# RL6678_IP_SVD register map
Vendor: Realtek
Registers are 32-bit, read-write, reset 0x0 unless marked. A register's access mark holds for its fields unless they carry their own. Offsets are from the block's base; [hi:lo] are bit positions; <NAME> marks a mode.

## TRNG_REG
Base 0x41009000
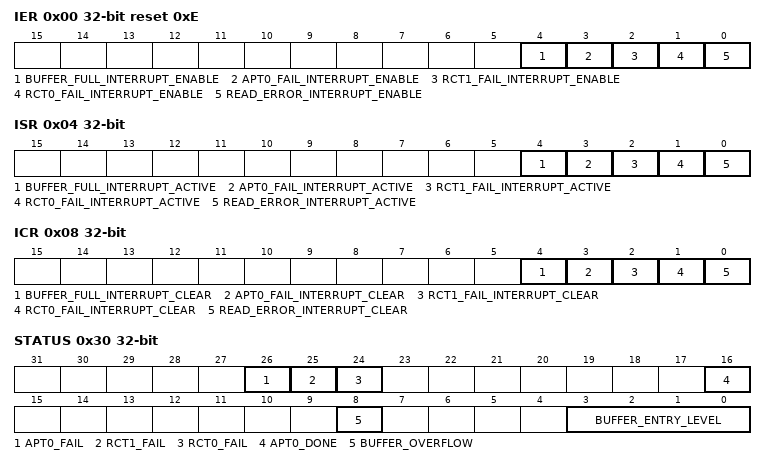
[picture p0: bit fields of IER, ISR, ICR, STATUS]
0x00 IER reset 0xE — Interrupt Enable Register
  [4] BUFFER_FULL_INTERRUPT_ENABLE — RNG buffer full interrupt enable
  [3] APT0_FAIL_INTERRUPT_ENABLE — Adaptive Proportion Test 0 fail interrupt enable
  [2] RCT1_FAIL_INTERRUPT_ENABLE — Repetition Count Test 1 fail interrupt enable
  [1] RCT0_FAIL_INTERRUPT_ENABLE — Repetition Count Test 0 fail interrupt enable
  [0] READ_ERROR_INTERRUPT_ENABLE — Read error interrupt enable. Trigger interrupt when reading RNG data register and RNG valid is not 0x1~0x8.
0x04 ISR ro — Interrupt Status Register
  [4] BUFFER_FULL_INTERRUPT_ACTIVE, [3] APT0_FAIL_INTERRUPT_ACTIVE, [2] RCT1_FAIL_INTERRUPT_ACTIVE, [1] RCT0_FAIL_INTERRUPT_ACTIVE, [0] READ_ERROR_INTERRUPT_ACTIVE
0x08 ICR wo — Interrupt Clear Register
  [4] BUFFER_FULL_INTERRUPT_CLEAR
  [3] APT0_FAIL_INTERRUPT_CLEAR — Clear the this interrupt also clear the error flags of APT0 health tests
  [2] RCT1_FAIL_INTERRUPT_CLEAR — Clear the this interrupt also clear the error flags of RCT1 health tests
  [1] RCT0_FAIL_INTERRUPT_CLEAR — Clear the this interrupt also clear the error flags of RCT0 health tests
  [0] READ_ERROR_INTERRUPT_CLEAR
0x0C FIFO_STATUS ro — Valid Register
  [3:0] RNG_VALID — Encoded status register. 0x0: buffer empty or APT is not done. 0x1~0x8: number of word are valid. 0xF: APT test fail
0x30 STATUS ro
  [26] APT0_FAIL — APT0 error detected
  [25] RCT1_FAIL — RCT1 error detected
  [24] RCT0_FAIL — RCT0 error detected
  [16] APT0_DONE — Adaptive Proportion Test done status. (APT test pass count >= APT done threshold setting)
  [8] BUFFER_OVERFLOW — Buffer overflow status. It is clear by RNG read out.
  [3:0] BUFFER_ENTRY_LEVEL — Number of 32-bit random number are valid. 0: empty 8: full
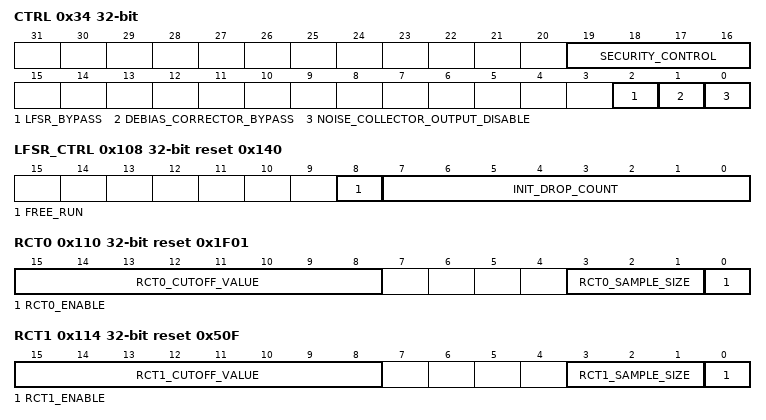
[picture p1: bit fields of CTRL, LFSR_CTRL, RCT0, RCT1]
0x34 CTRL — Control Register
  [19:16] SECURITY_CONTROL — If this field is equal to 0xA, the TRNG become a non-secure slave, and all the registers can be accessed by non-secure transaction. If this field is not equal to 0xA, the non-seucre transaction can only access address 0xC~0x30.
  [2] LFSR_BYPASS — LFSR bypass enable
  [1] DEBIAS_CORRECTOR_BYPASS — Debias corrector bypass enable
  [0] NOISE_COLLECTOR_OUTPUT_DISABLE
0x38 SW_RST wo — Software Reset Register
  [0] SW_RESET — Write 1 to trigger software reset.
0x108 LFSR_CTRL reset 0x140 — LFSR Control Register
  [8] FREE_RUN — 0x1: continuously run LFSR when no input data 0x0: only shift LFSR when input 1 bit data
  [7:0] INIT_DROP_COUNT — Discard number of bit after reset or re-init. Default shift out 64 bits in LFSR.
0x110 RCT0 reset 0x1F01 — Repetition Count Test 0 Control Register
  [15:8] RCT0_CUTOFF_VALUE — Cutoff value
  [3:1] RCT0_SAMPLE_SIZE — Number of bit per test sample. The sample size is the value add 1. 0: 1-bit 1: 2-bit ... 7: 8-bit
  [0] RCT0_ENABLE — Test enable
0x114 RCT1 reset 0x50F — Repetition Count Test 1 Control Register
  [15:8] RCT1_CUTOFF_VALUE — Cutoff value
  [3:1] RCT1_SAMPLE_SIZE — Number of bit per test sample. The sample size is the value add 1. 0: 1-bit 1: 2-bit ... 7: 8-bit
  [0] RCT1_ENABLE — Test enable
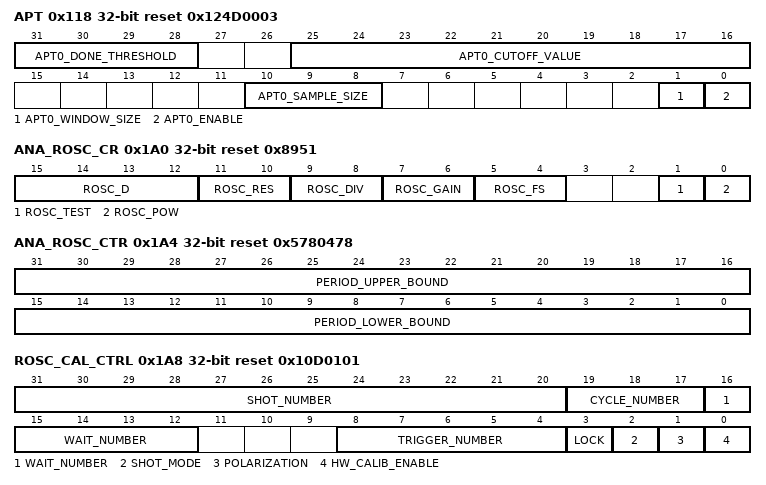
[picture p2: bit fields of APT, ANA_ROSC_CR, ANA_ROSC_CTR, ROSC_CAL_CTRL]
0x118 APT reset 0x124D0003 — Adaptive Proportion Test Control Register
  [31:28] APT0_DONE_THRESHOLD — Assert test done after how many test pass
  [25:16] APT0_CUTOFF_VALUE — Cutoff value
  [10:8] APT0_SAMPLE_SIZE — Number of bit per test sample. The sample size is the value add 1. 0: 1-bit 1: 2-bit ... 7: 8-bit
  [1] APT0_WINDOW_SIZE — 0: 512 bits 1: 1024 bits
  [0] APT0_ENABLE — Test enable
0x1A0 ANA_ROSC_CR reset 0x8951 — Analog ROSC Control Register
  [15:12] ROSC_D — (ROSC ISEL) ROSC calibration input data by F/W
  [11:10] ROSC_RES — ROSC noise resistor selection
  [9:8] ROSC_DIV — ROSC clock divider control register. 00: div1 01: div2 10: div3 11: div4
  [7:6] ROSC_GAIN — ROSC noise gain control
  [5:4] ROSC_FS — ROSC frequency range control register
  [1] ROSC_TEST — ROSC analog test signal enable
  [0] ROSC_POW — ROSC power-on control register
0x1A4 ANA_ROSC_CTR reset 0x5780478 — Analog ROSC Calibration Threshold Register
  [31:16] PERIOD_UPPER_BOUND — Calibration Period Upper Bound. The counter is clocked by bus clock to measure CLKOUT_ROSC period.
  [15:0] PERIOD_LOWER_BOUND — Calibration Period Lower Bound. If counter value < lower bound, the CLKOUT_ROSC frequency is too high.
0x1A8 ROSC_CAL_CTRL reset 0x10D0101 — ROSC Calibration Control Register
  [31:20] SHOT_NUMBER
  [19:17] CYCLE_NUMBER — 0x6 = 128 cycles. (this is an encode value). Number of ROSC clock cycle to trigger one calibration
  [16:12] WAIT_NUMBER — After ROSC_D change, the wait cycle number before next calibration procedure. It need to take about 1us to make the OSC stable.
  [8:4] TRIGGER_NUMBER — The value of ROSC_D will be adjusted if CKOUT_ROSC is too high/low more than trig_num times.
  [3] LOCK — Force rosc_lock to 1. The NS start to sample when rosc_lock is high. The lock indicate the OCS is stable measure by sensor.
  [2] SHOT_MODE
  [1] POLARIZATION — Polarization of ROSC_D in Calibration. 0: too low -> ROSC_D increases 1: too high -> ROSC_D decreases
  [0] HW_CALIB_ENABLE — 1: control ROSC_D by HW sensor logic. 0: control ROSC_D by SW.
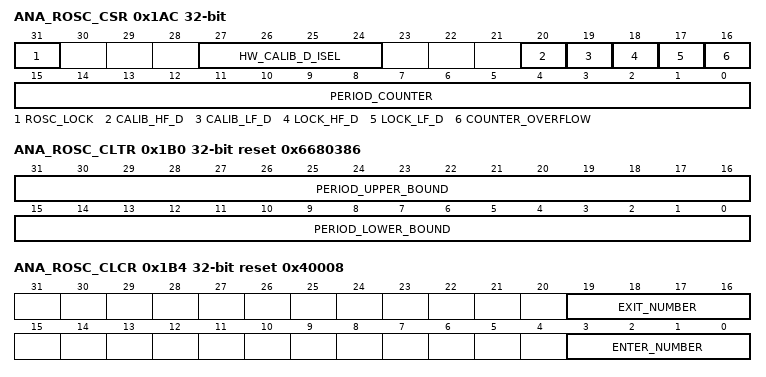
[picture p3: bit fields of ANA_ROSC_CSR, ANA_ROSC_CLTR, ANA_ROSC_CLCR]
0x1AC ANA_ROSC_CSR ro — Analog ROSC Calibration Status Register
  [31] ROSC_LOCK — ROSC is LOCK. It means CKOUT_ROSC is stable
  [27:24] HW_CALIB_D_ISEL — The value of ROSC_D generated by Speed Sensor hardware
  [20] CALIB_HF_D
  [19] CALIB_LF_D
  [18] LOCK_HF_D
  [17] LOCK_LF_D
  [16] COUNTER_OVERFLOW — The Period Counter for last CKOUT_ROSC is overflow
  [15:0] PERIOD_COUNTER — The Value of Period Counter for last CKOUT_ROSC
0x1B0 ANA_ROSC_CLTR reset 0x6680386 — Analog ROSC Calibration Lock Threshold Register
  [31:16] PERIOD_UPPER_BOUND — Locked Clock Period Upper Bound. To check the ROSC is stable.
  [15:0] PERIOD_LOWER_BOUND — Locked Clock Period Lower Bound. The sensor checks the frequency in the range several times(exit/enter num) to assert rosc_lock.
0x1B4 ANA_ROSC_CLCR reset 0x40008 — Analog ROSC Calibration Lock Control Register
  [19:16] EXIT_NUMBER — Number of times that clock period continuously out of range to causes rosc_lock de-asserted
  [3:0] ENTER_NUMBER — Number of times that clock period continuously in range to causes rosc_lock asserted
0x1B8 ANA_ROSC_CSRR wo — Analog ROSC Calibration Sensor Reset Register
  [0] ROSC_CALIBRATION_SENSOR_RESET — Reset analog ROSC calibration sensor; Write 1 to reset sensor
